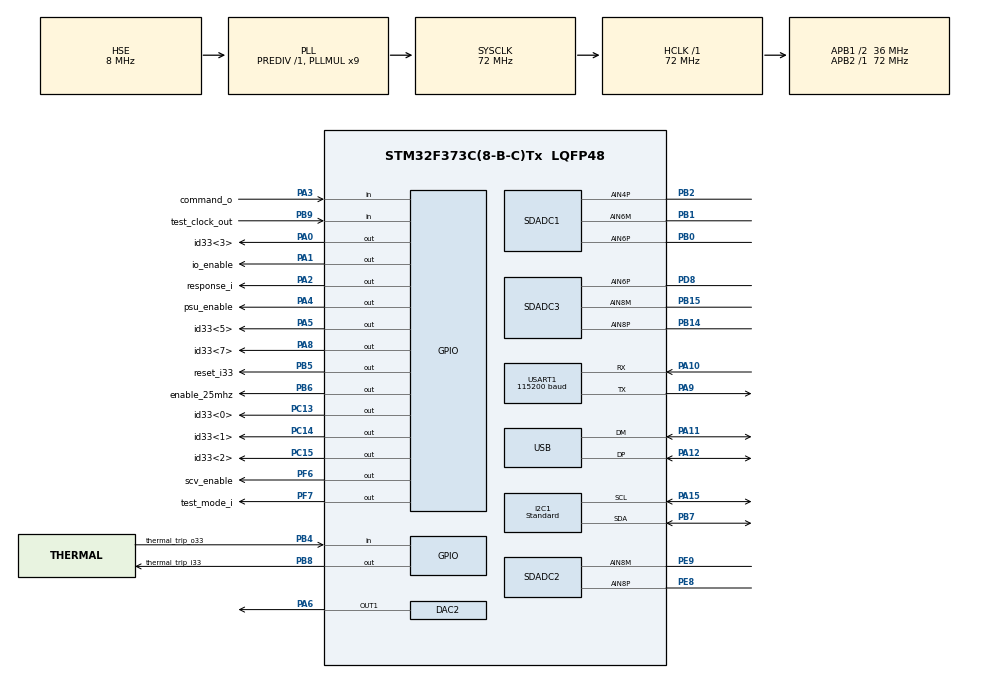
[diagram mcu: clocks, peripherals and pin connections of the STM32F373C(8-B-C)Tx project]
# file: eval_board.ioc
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ADC1.Channel-0\#ChannelRegularConversion=ADC_CHANNEL_TEMPSENSOR
ADC1.NbrOfConversionFlag=1
ADC1.Rank-0\#ChannelRegularConversion=1
ADC1.SamplingTime-0\#ChannelRegularConversion=ADC_SAMPLETIME_1CYCLE_5
ADC1.master=1
Dma.Request0=USART1_RX
Dma.Request1=USART1_TX
Dma.USART1_RX.0.Direction=DMA_PERIPH_TO_MEMORY
Dma.USART1_RX.0.Instance=DMA1_Channel5
Dma.USART1_RX.0.MemDataAlignment=DMA_MDATAALIGN_BYTE
Dma.USART1_RX.0.MemInc=DMA_MINC_ENABLE
Dma.USART1_RX.0.Mode=DMA_CIRCULAR
Dma.USART1_RX.0.PeriphDataAlignment=DMA_PDATAALIGN_BYTE
Dma.USART1_RX.0.PeriphInc=DMA_PINC_DISABLE
Dma.USART1_RX.0.Priority=DMA_PRIORITY_LOW
Dma.USART1_TX.1.Direction=DMA_MEMORY_TO_PERIPH
Dma.USART1_TX.1.Instance=DMA1_Channel4
Dma.USART1_TX.1.MemDataAlignment=DMA_MDATAALIGN_BYTE
Dma.USART1_TX.1.MemInc=DMA_MINC_ENABLE
Dma.USART1_TX.1.Mode=DMA_NORMAL
Dma.USART1_TX.1.PeriphDataAlignment=DMA_PDATAALIGN_BYTE
Dma.USART1_TX.1.PeriphInc=DMA_PINC_DISABLE
Dma.USART1_TX.1.Priority=DMA_PRIORITY_LOW
I2C1.I2C_Speed_Mode=I2C_Standard
Mcu.Family=STM32F3
Mcu.Name=STM32F373C(8-B-C)Tx
Mcu.Package=LQFP48
NVIC.DMA1_Channel4_IRQn=true\:0\:0\:false\:false\:true\:false\:true\:true
NVIC.DMA1_Channel5_IRQn=true\:0\:0\:false\:false\:true\:false\:true\:true
NVIC.PriorityGroup=NVIC_PRIORITYGROUP_4
NVIC.SDADC1_IRQn=true\:0\:0\:false\:false\:true\:true\:true\:true
NVIC.USART1_IRQn=true\:0\:0\:false\:false\:true\:true\:true\:true
NVIC.USB_LP_IRQn=true\:0\:0\:false\:false\:true\:false\:true\:true
PA0.GPIO_Label=id33<3>
PA0.Signal=GPIO_Output
PA1.GPIO_Label=io_enable
PA1.Signal=GPIO_Output
PA10.Mode=Asynchronous
PA10.Signal=USART1_RX
PA11.Mode=Device
PA11.Signal=USB_DM
PA12.Mode=Device
PA12.Signal=USB_DP
PA13.Mode=Trace_Asynchronous_SW
PA13.Signal=SYS_JTMS-SWDIO
PA14.Mode=Trace_Asynchronous_SW
PA14.Signal=SYS_JTCK-SWCLK
PA15.Mode=I2C
PA15.Signal=I2C1_SCL
PA2.GPIO_Label=response_i
PA2.Signal=GPIO_Output
PA3.GPIO_Label=command_o
PA3.Signal=GPIO_Input
PA4.GPIO_Label=psu_enable
PA4.Signal=GPIO_Output
PA5.GPIO_Label=id33<5>
PA5.Signal=GPIO_Output
PA6.Signal=COMP_DAC21_group
PA8.GPIO_Label=id33<7>
PA8.Signal=GPIO_Output
PA9.Mode=Asynchronous
PA9.Signal=USART1_TX
PB0.Mode=IN6-Differential
PB0.Signal=SDADC1_AIN6P
PB1.Mode=IN6-Differential
PB1.Signal=SDADC1_AIN6M
PB14.Mode=IN8-Differential
PB14.Signal=SDADC3_AIN8P
PB15.Mode=IN8-Differential
PB15.Signal=SDADC3_AIN8M
PB2.Mode=IN4-Single-Ended
PB2.Signal=SDADC1_AIN4P
PB3.Mode=Trace_Asynchronous_SW
PB3.Signal=SYS_JTDO-TRACESWO
PB4.GPIO_Label=thermal_trip_o33
PB4.GPIO_PuPd=GPIO_PULLUP
PB4.Signal=GPIO_Input
PB5.GPIO_Label=reset_i33
PB5.Signal=GPIO_Output
PB6.GPIO_Label=enable_25mhz
PB6.Signal=GPIO_Output
PB7.Mode=I2C
PB7.Signal=I2C1_SDA
PB8.GPIO_Label=thermal_trip_i33
PB8.Signal=GPIO_Output
PB9.GPIO_Label=test_clock_out
PB9.GPIO_PuPd=GPIO_PULLDOWN
PB9.Signal=GPIO_Input
PC13.GPIO_Label=id33<0>
PC13.Signal=GPIO_Output
PC14-OSC32_IN.GPIO_Label=id33<1>
PC14-OSC32_IN.Signal=GPIO_Output
PC15-OSC32_OUT.GPIO_Label=id33<2>
PC15-OSC32_OUT.Signal=GPIO_Output
PD8.Mode=IN6-Single-Ended
PD8.Signal=SDADC3_AIN6P
PE8.Mode=IN8-Differential
PE8.Signal=SDADC2_AIN8P
PE9.Mode=IN8-Differential
PE9.Signal=SDADC2_AIN8M
PF0-OSC_IN.Mode=HSE-External-Oscillator
PF0-OSC_IN.Signal=RCC_OSC_IN
PF1-OSC_OUT.Mode=HSE-External-Oscillator
PF1-OSC_OUT.Signal=RCC_OSC_OUT
PF6.GPIO_Label=scv_enable
PF6.Signal=GPIO_Output
PF7.GPIO_Label=test_mode_i
PF7.Signal=GPIO_Output
ProjectManager.HeapSize=0x800
ProjectManager.StackSize=0x800
ProjectManager.TargetToolchain=STM32CubeIDE
RCC.AHBFreq_Value=72000000
RCC.APB1CLKDivider=RCC_HCLK_DIV2
RCC.APB1Freq_Value=36000000
RCC.APB1TimFreq_Value=72000000
RCC.APB2Freq_Value=72000000
RCC.APB2TimFreq_Value=72000000
RCC.CortexFreq_Value=72000000
RCC.HCLKFreq_Value=72000000
RCC.HSE_VALUE=8000000
RCC.HSI_VALUE=8000000
RCC.LSE_VALUE=32768
RCC.PLLMUL=RCC_PLL_MUL9
RCC.PRESCALERUSB=RCC_USBCLKSOURCE_PLL_DIV1_5
RCC.SDADCPresc=RCC_SDADCSYSCLK_DIV12
RCC.SYSCLKFreq_VALUE=72000000
RCC.SYSCLKSource=RCC_SYSCLKSOURCE_PLLCLK
RCC.USBFreq_Value=48000000
SDADC1.Channel-0\#ChannelRegularConversion=SDADC_CHANNEL_6
SDADC1.ConfIndex-0\#ChannelRegularConversion=SDADC_CONF_INDEX_0
SDADC1.ContinuousMode=SDADC_CONTINUOUS_CONV_ON
SDADC1.EnableRegularconversion=ENABLE
SDADC1.FastConversionMode=SDADC_FAST_CONV_ENABLE
SDADC1.Gain0=SDADC_GAIN_8
SDADC1.Gain1=SDADC_GAIN_4
SDADC1.InputMode1=SDADC_INPUT_MODE_SE_OFFSET
SDADC1.NbrOfConversionFlag=1
SDADC1.ReferenceVoltage=SDADC_VREF_VDDA
SDADC2.ContinuousMode=SDADC_CONTINUOUS_CONV_ON
SDADC2.EnableRegularconversion=ENABLE
SDADC2.FastConversionMode=SDADC_FAST_CONV_ENABLE
SDADC2.Gain0=SDADC_GAIN_8
SDADC2.NbrOfConversionFlag=1
SDADC2.ReferenceVoltage=SDADC_VREF_VDDA
SDADC2.Trigger=SDADC_SOFTWARE_TRIGGER
SDADC3.Channel-0\#ChannelRegularConversion=SDADC_CHANNEL_8
SDADC3.ConfIndex-0\#ChannelRegularConversion=SDADC_CONF_INDEX_0
SDADC3.ContinuousMode=SDADC_CONTINUOUS_CONV_ON
SDADC3.EnableRegularconversion=ENABLE
SDADC3.FastConversionMode=SDADC_FAST_CONV_ENABLE
SDADC3.Gain0=SDADC_GAIN_8
SDADC3.Gain1=SDADC_GAIN_4
SDADC3.InputMode1=SDADC_INPUT_MODE_SE_OFFSET
SDADC3.NbrOfConversionFlag=1
SDADC3.ReferenceVoltage=SDADC_VREF_VDDA
SH.COMP_DAC21_group.0=DAC2_OUT1,DAC_OUT1
USART1.BaudRate=115200
USART1.OverSampling=UART_OVERSAMPLING_8
USART1.VirtualMode-Asynchronous=VM_ASYNC
USB_DEVICE.CLASS_NAME_FS=CDC
USB_DEVICE.VirtualMode=Cdc
USB_DEVICE.VirtualModeFS=Cdc_FS
VP_ADC1_TempSens_Input.Mode=IN-TempSens
VP_SDADC1_CONF0.Mode=ConfigZero
VP_SDADC1_CONF1.Mode=ConfigUn
VP_SDADC2_CONF0.Mode=ConfigZero
VP_SDADC3_CONF0.Mode=ConfigZero
VP_SDADC3_CONF1.Mode=ConfigUn
VP_USB_DEVICE_VS_USB_DEVICE_CDC_FS.Mode=CDC_FS
board=custom

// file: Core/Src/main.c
/* USER CODE BEGIN Header */
/**
  ******************************************************************************
  * @file           : main.c
  * @brief          : Main program body
  ******************************************************************************
  * @attention
  *
  * Copyright (c) 2022 STMicroelectronics.
  * All rights reserved.
  *
  * This software is licensed under terms that can be found in the LICENSE file
  * in the root directory of this software component.
  * If no LICENSE file comes with this software, it is provided AS-IS.
  *
  ******************************************************************************
  */
/* USER CODE END Header */
#include "main.h"
#include "usb_device.h"

/* USER CODE BEGIN Includes */
#include "../../../uctl_common/ssd1306.h"

/* USER CODE END Includes */

ADC_HandleTypeDef hadc1;

DAC_HandleTypeDef hdac2;

I2C_HandleTypeDef hi2c1;

SDADC_HandleTypeDef hsdadc1;
SDADC_HandleTypeDef hsdadc2;
SDADC_HandleTypeDef hsdadc3;

UART_HandleTypeDef huart1;
DMA_HandleTypeDef hdma_usart1_rx;
DMA_HandleTypeDef hdma_usart1_tx;

void SystemClock_Config(void);
static void MX_GPIO_Init(void);
static void MX_DMA_Init(void);
static void MX_SDADC1_Init(void);
static void MX_SDADC2_Init(void);
static void MX_USART1_UART_Init(void);
static void MX_DAC2_Init(void);
static void MX_I2C1_Init(void);
static void MX_SDADC3_Init(void);
static void MX_ADC1_Init(void);

/* USER CODE BEGIN 0 */
void Init();
void Loop();
/* USER CODE END 0 */

int main(void)
{

  /* MCU Configuration--------------------------------------------------------*/

  /* Reset of all peripherals, Initializes the Flash interface and the Systick. */
  HAL_Init();

  /* Configure the system clock */
  SystemClock_Config();

  /* Initialize all configured peripherals */
  MX_GPIO_Init();
  MX_DMA_Init();
  MX_SDADC1_Init();
  MX_SDADC2_Init();
  MX_USART1_UART_Init();
  MX_DAC2_Init();
  MX_USB_DEVICE_Init();
  MX_I2C1_Init();
  MX_SDADC3_Init();
  MX_ADC1_Init();
  /* USER CODE BEGIN 2 */

  Init();

  /* USER CODE END 2 */

  /* Infinite loop */
  while (1)
  {

    /* USER CODE BEGIN 3 */
      Loop();
  }
  /* USER CODE END 3 */
}

void SystemClock_Config(void)
{
  RCC_OscInitTypeDef RCC_OscInitStruct = {0};
  RCC_ClkInitTypeDef RCC_ClkInitStruct = {0};
  RCC_PeriphCLKInitTypeDef PeriphClkInit = {0};

  /** Initializes the RCC Oscillators according to the specified parameters
  * in the RCC_OscInitTypeDef structure.
  */
  RCC_OscInitStruct.OscillatorType = RCC_OSCILLATORTYPE_HSI|RCC_OSCILLATORTYPE_HSE;
  RCC_OscInitStruct.HSEState = RCC_HSE_ON;
  RCC_OscInitStruct.HSEPredivValue = RCC_HSE_PREDIV_DIV1;
  RCC_OscInitStruct.HSIState = RCC_HSI_ON;
  RCC_OscInitStruct.HSICalibrationValue = RCC_HSICALIBRATION_DEFAULT;
  RCC_OscInitStruct.PLL.PLLState = RCC_PLL_ON;
  RCC_OscInitStruct.PLL.PLLSource = RCC_PLLSOURCE_HSE;
  RCC_OscInitStruct.PLL.PLLMUL = RCC_PLL_MUL9;
  if (HAL_RCC_OscConfig(&RCC_OscInitStruct) != HAL_OK)
  {
    Error_Handler();
  }

  /** Initializes the CPU, AHB and APB buses clocks
  */
  RCC_ClkInitStruct.ClockType = RCC_CLOCKTYPE_HCLK|RCC_CLOCKTYPE_SYSCLK
                              |RCC_CLOCKTYPE_PCLK1|RCC_CLOCKTYPE_PCLK2;
  RCC_ClkInitStruct.SYSCLKSource = RCC_SYSCLKSOURCE_PLLCLK;
  RCC_ClkInitStruct.AHBCLKDivider = RCC_SYSCLK_DIV1;
  RCC_ClkInitStruct.APB1CLKDivider = RCC_HCLK_DIV2;
  RCC_ClkInitStruct.APB2CLKDivider = RCC_HCLK_DIV1;

  if (HAL_RCC_ClockConfig(&RCC_ClkInitStruct, FLASH_LATENCY_2) != HAL_OK)
  {
    Error_Handler();
  }
  PeriphClkInit.PeriphClockSelection = RCC_PERIPHCLK_USB|RCC_PERIPHCLK_USART1
                              |RCC_PERIPHCLK_I2C1|RCC_PERIPHCLK_ADC1
                              |RCC_PERIPHCLK_SDADC;
  PeriphClkInit.Usart1ClockSelection = RCC_USART1CLKSOURCE_PCLK2;
  PeriphClkInit.I2c1ClockSelection = RCC_I2C1CLKSOURCE_HSI;
  PeriphClkInit.USBClockSelection = RCC_USBCLKSOURCE_PLL_DIV1_5;
  PeriphClkInit.SdadcClockSelection = RCC_SDADCSYSCLK_DIV12;
  PeriphClkInit.Adc1ClockSelection = RCC_ADC1PCLK2_DIV2;

  if (HAL_RCCEx_PeriphCLKConfig(&PeriphClkInit) != HAL_OK)
  {
    Error_Handler();
  }
  HAL_PWREx_EnableSDADC(PWR_SDADC_ANALOG1);
  HAL_PWREx_EnableSDADC(PWR_SDADC_ANALOG2);
  HAL_PWREx_EnableSDADC(PWR_SDADC_ANALOG3);
}

static void MX_ADC1_Init(void)
{

  ADC_ChannelConfTypeDef sConfig = {0};

  /** Common config
  */
  hadc1.Instance = ADC1;
  hadc1.Init.ScanConvMode = ADC_SCAN_DISABLE;
  hadc1.Init.ContinuousConvMode = DISABLE;
  hadc1.Init.DiscontinuousConvMode = DISABLE;
  hadc1.Init.ExternalTrigConv = ADC_SOFTWARE_START;
  hadc1.Init.DataAlign = ADC_DATAALIGN_RIGHT;
  hadc1.Init.NbrOfConversion = 1;
  if (HAL_ADC_Init(&hadc1) != HAL_OK)
  {
    Error_Handler();
  }

  /** Configure Regular Channel
  */
  sConfig.Channel = ADC_CHANNEL_TEMPSENSOR;
  sConfig.Rank = ADC_REGULAR_RANK_1;
  sConfig.SamplingTime = ADC_SAMPLETIME_1CYCLE_5;
  if (HAL_ADC_ConfigChannel(&hadc1, &sConfig) != HAL_OK)
  {
    Error_Handler();
  }

}

static void MX_DAC2_Init(void)
{

  DAC_ChannelConfTypeDef sConfig = {0};

  /** DAC Initialization
  */
  hdac2.Instance = DAC2;
  if (HAL_DAC_Init(&hdac2) != HAL_OK)
  {
    Error_Handler();
  }

  /** DAC channel OUT1 config
  */
  sConfig.DAC_Trigger = DAC_TRIGGER_NONE;
  sConfig.DAC_OutputBuffer = DAC_OUTPUTBUFFER_ENABLE;
  if (HAL_DAC_ConfigChannel(&hdac2, &sConfig, DAC_CHANNEL_1) != HAL_OK)
  {
    Error_Handler();
  }

}

static void MX_I2C1_Init(void)
{

  hi2c1.Instance = I2C1;
  hi2c1.Init.Timing = 0x2000090E;
  hi2c1.Init.OwnAddress1 = 0;
  hi2c1.Init.AddressingMode = I2C_ADDRESSINGMODE_7BIT;
  hi2c1.Init.DualAddressMode = I2C_DUALADDRESS_DISABLE;
  hi2c1.Init.OwnAddress2 = 0;
  hi2c1.Init.OwnAddress2Masks = I2C_OA2_NOMASK;
  hi2c1.Init.GeneralCallMode = I2C_GENERALCALL_DISABLE;
  hi2c1.Init.NoStretchMode = I2C_NOSTRETCH_DISABLE;
  if (HAL_I2C_Init(&hi2c1) != HAL_OK)
  {
    Error_Handler();
  }

  /** Configure Analogue filter
  */
  if (HAL_I2CEx_ConfigAnalogFilter(&hi2c1, I2C_ANALOGFILTER_ENABLE) != HAL_OK)
  {
    Error_Handler();
  }

  /** Configure Digital filter
  */
  if (HAL_I2CEx_ConfigDigitalFilter(&hi2c1, 0) != HAL_OK)
  {
    Error_Handler();
  }

}

static void MX_SDADC1_Init(void)
{

  SDADC_ConfParamTypeDef ConfParamStruct = {0};

  /** Configure the SDADC low power mode, fast conversion mode,
  slow clock mode and SDADC1 reference voltage
  */
  hsdadc1.Instance = SDADC1;
  hsdadc1.Init.IdleLowPowerMode = SDADC_LOWPOWER_NONE;
  hsdadc1.Init.FastConversionMode = SDADC_FAST_CONV_ENABLE;
  hsdadc1.Init.SlowClockMode = SDADC_SLOW_CLOCK_DISABLE;
  hsdadc1.Init.ReferenceVoltage = SDADC_VREF_VDDA;
  if (HAL_SDADC_Init(&hsdadc1) != HAL_OK)
  {
    Error_Handler();
  }

  /** Configure The Regular Mode
  */
  if (HAL_SDADC_SelectRegularTrigger(&hsdadc1, SDADC_SOFTWARE_TRIGGER) != HAL_OK)
  {
    Error_Handler();
  }

  /** Set parameters for SDADC configuration 0 Register
  */
  ConfParamStruct.InputMode = SDADC_INPUT_MODE_DIFF;
  ConfParamStruct.Gain = SDADC_GAIN_8;
  ConfParamStruct.CommonMode = SDADC_COMMON_MODE_VSSA;
  ConfParamStruct.Offset = 0;
  if (HAL_SDADC_PrepareChannelConfig(&hsdadc1, SDADC_CONF_INDEX_0, &ConfParamStruct) != HAL_OK)
  {
    Error_Handler();
  }

  /** Set parameters for SDADC configuration 1 Register
  */
  ConfParamStruct.InputMode = SDADC_INPUT_MODE_SE_OFFSET;
  ConfParamStruct.Gain = SDADC_GAIN_4;
  if (HAL_SDADC_PrepareChannelConfig(&hsdadc1, SDADC_CONF_INDEX_1, &ConfParamStruct) != HAL_OK)
  {
    Error_Handler();
  }

  /** Configure the Regular Channel
  */
  if (HAL_SDADC_AssociateChannelConfig(&hsdadc1, SDADC_CHANNEL_6, SDADC_CONF_INDEX_0) != HAL_OK)
  {
    Error_Handler();
  }
  if (HAL_SDADC_ConfigChannel(&hsdadc1, SDADC_CHANNEL_6, SDADC_CONTINUOUS_CONV_ON) != HAL_OK)
  {
    Error_Handler();
  }

}

static void MX_SDADC2_Init(void)
{

  SDADC_ConfParamTypeDef ConfParamStruct = {0};

  /** Configure the SDADC low power mode, fast conversion mode,
  slow clock mode and SDADC1 reference voltage
  */
  hsdadc2.Instance = SDADC2;
  hsdadc2.Init.IdleLowPowerMode = SDADC_LOWPOWER_NONE;
  hsdadc2.Init.FastConversionMode = SDADC_FAST_CONV_ENABLE;
  hsdadc2.Init.SlowClockMode = SDADC_SLOW_CLOCK_DISABLE;
  hsdadc2.Init.ReferenceVoltage = SDADC_VREF_VDDA;
  if (HAL_SDADC_Init(&hsdadc2) != HAL_OK)
  {
    Error_Handler();
  }

  /** Configure The Regular Mode
  */
  if (HAL_SDADC_SelectRegularTrigger(&hsdadc2, SDADC_SOFTWARE_TRIGGER) != HAL_OK)
  {
    Error_Handler();
  }

  /** Set parameters for SDADC configuration 0 Register
  */
  ConfParamStruct.InputMode = SDADC_INPUT_MODE_DIFF;
  ConfParamStruct.Gain = SDADC_GAIN_8;
  ConfParamStruct.CommonMode = SDADC_COMMON_MODE_VSSA;
  ConfParamStruct.Offset = 0;
  if (HAL_SDADC_PrepareChannelConfig(&hsdadc2, SDADC_CONF_INDEX_0, &ConfParamStruct) != HAL_OK)
  {
    Error_Handler();
  }

}

static void MX_SDADC3_Init(void)
{

  SDADC_ConfParamTypeDef ConfParamStruct = {0};

  /** Configure the SDADC low power mode, fast conversion mode,
  slow clock mode and SDADC1 reference voltage
  */
  hsdadc3.Instance = SDADC3;
  hsdadc3.Init.IdleLowPowerMode = SDADC_LOWPOWER_NONE;
  hsdadc3.Init.FastConversionMode = SDADC_FAST_CONV_ENABLE;
  hsdadc3.Init.SlowClockMode = SDADC_SLOW_CLOCK_DISABLE;
  hsdadc3.Init.ReferenceVoltage = SDADC_VREF_VDDA;
  if (HAL_SDADC_Init(&hsdadc3) != HAL_OK)
  {
    Error_Handler();
  }

  /** Configure The Regular Mode
  */
  if (HAL_SDADC_SelectRegularTrigger(&hsdadc3, SDADC_SOFTWARE_TRIGGER) != HAL_OK)
  {
    Error_Handler();
  }

  /** Set parameters for SDADC configuration 0 Register
  */
  ConfParamStruct.InputMode = SDADC_INPUT_MODE_DIFF;
  ConfParamStruct.Gain = SDADC_GAIN_8;
  ConfParamStruct.CommonMode = SDADC_COMMON_MODE_VSSA;
  ConfParamStruct.Offset = 0;
  if (HAL_SDADC_PrepareChannelConfig(&hsdadc3, SDADC_CONF_INDEX_0, &ConfParamStruct) != HAL_OK)
  {
    Error_Handler();
  }

  /** Set parameters for SDADC configuration 1 Register
  */
  ConfParamStruct.InputMode = SDADC_INPUT_MODE_SE_OFFSET;
  ConfParamStruct.Gain = SDADC_GAIN_4;
  if (HAL_SDADC_PrepareChannelConfig(&hsdadc3, SDADC_CONF_INDEX_1, &ConfParamStruct) != HAL_OK)
  {
    Error_Handler();
  }

  /** Configure the Regular Channel
  */
  if (HAL_SDADC_AssociateChannelConfig(&hsdadc3, SDADC_CHANNEL_8, SDADC_CONF_INDEX_0) != HAL_OK)
  {
    Error_Handler();
  }
  if (HAL_SDADC_ConfigChannel(&hsdadc3, SDADC_CHANNEL_8, SDADC_CONTINUOUS_CONV_ON) != HAL_OK)
  {
    Error_Handler();
  }

}

static void MX_USART1_UART_Init(void)
{

  huart1.Instance = USART1;
  huart1.Init.BaudRate = 115200;
  huart1.Init.WordLength = UART_WORDLENGTH_8B;
  huart1.Init.StopBits = UART_STOPBITS_1;
  huart1.Init.Parity = UART_PARITY_NONE;
  huart1.Init.Mode = UART_MODE_TX_RX;
  huart1.Init.HwFlowCtl = UART_HWCONTROL_NONE;
  huart1.Init.OverSampling = UART_OVERSAMPLING_8;
  huart1.Init.OneBitSampling = UART_ONE_BIT_SAMPLE_DISABLE;
  huart1.AdvancedInit.AdvFeatureInit = UART_ADVFEATURE_NO_INIT;
  if (HAL_UART_Init(&huart1) != HAL_OK)
  {
    Error_Handler();
  }

}

static void MX_DMA_Init(void)
{

  /* DMA controller clock enable */
  __HAL_RCC_DMA1_CLK_ENABLE();

  /* DMA interrupt init */
  /* DMA1_Channel4_IRQn interrupt configuration */
  HAL_NVIC_SetPriority(DMA1_Channel4_IRQn, 0, 0);
  HAL_NVIC_EnableIRQ(DMA1_Channel4_IRQn);
  /* DMA1_Channel5_IRQn interrupt configuration */
  HAL_NVIC_SetPriority(DMA1_Channel5_IRQn, 0, 0);
  HAL_NVIC_EnableIRQ(DMA1_Channel5_IRQn);

}

static void MX_GPIO_Init(void)
{
  GPIO_InitTypeDef GPIO_InitStruct = {0};

  /* GPIO Ports Clock Enable */
  __HAL_RCC_GPIOC_CLK_ENABLE();
  __HAL_RCC_GPIOF_CLK_ENABLE();
  __HAL_RCC_GPIOA_CLK_ENABLE();
  __HAL_RCC_GPIOB_CLK_ENABLE();
  __HAL_RCC_GPIOE_CLK_ENABLE();
  __HAL_RCC_GPIOD_CLK_ENABLE();

  /*Configure GPIO pin Output Level */
  HAL_GPIO_WritePin(GPIOC, id33_0__Pin|id33_1__Pin|id33_2__Pin, GPIO_PIN_RESET);

  /*Configure GPIO pin Output Level */
  HAL_GPIO_WritePin(GPIOA, id33_3__Pin|io_enable_Pin|response_i_Pin|psu_enable_Pin
                          |id33_5__Pin|id33_7__Pin, GPIO_PIN_RESET);

  /*Configure GPIO pin Output Level */
  HAL_GPIO_WritePin(GPIOF, scv_enable_Pin|test_mode_i_Pin, GPIO_PIN_RESET);

  /*Configure GPIO pin Output Level */
  HAL_GPIO_WritePin(GPIOB, reset_i33_Pin|enable_25mhz_Pin|thermal_trip_i33_Pin, GPIO_PIN_RESET);

  /*Configure GPIO pins : id33_0__Pin id33_1__Pin id33_2__Pin */
  GPIO_InitStruct.Pin = id33_0__Pin|id33_1__Pin|id33_2__Pin;
  GPIO_InitStruct.Mode = GPIO_MODE_OUTPUT_PP;
  GPIO_InitStruct.Pull = GPIO_NOPULL;
  GPIO_InitStruct.Speed = GPIO_SPEED_FREQ_LOW;
  HAL_GPIO_Init(GPIOC, &GPIO_InitStruct);

  /*Configure GPIO pins : id33_3__Pin io_enable_Pin response_i_Pin psu_enable_Pin
                           id33_5__Pin id33_7__Pin */
  GPIO_InitStruct.Pin = id33_3__Pin|io_enable_Pin|response_i_Pin|psu_enable_Pin
                          |id33_5__Pin|id33_7__Pin;
  GPIO_InitStruct.Mode = GPIO_MODE_OUTPUT_PP;
  GPIO_InitStruct.Pull = GPIO_NOPULL;
  GPIO_InitStruct.Speed = GPIO_SPEED_FREQ_LOW;
  HAL_GPIO_Init(GPIOA, &GPIO_InitStruct);

  /*Configure GPIO pin : command_o_Pin */
  GPIO_InitStruct.Pin = command_o_Pin;
  GPIO_InitStruct.Mode = GPIO_MODE_INPUT;
  GPIO_InitStruct.Pull = GPIO_NOPULL;
  HAL_GPIO_Init(command_o_GPIO_Port, &GPIO_InitStruct);

  /*Configure GPIO pins : scv_enable_Pin test_mode_i_Pin */
  GPIO_InitStruct.Pin = scv_enable_Pin|test_mode_i_Pin;
  GPIO_InitStruct.Mode = GPIO_MODE_OUTPUT_PP;
  GPIO_InitStruct.Pull = GPIO_NOPULL;
  GPIO_InitStruct.Speed = GPIO_SPEED_FREQ_LOW;
  HAL_GPIO_Init(GPIOF, &GPIO_InitStruct);

  /*Configure GPIO pin : thermal_trip_o33_Pin */
  GPIO_InitStruct.Pin = thermal_trip_o33_Pin;
  GPIO_InitStruct.Mode = GPIO_MODE_INPUT;
  GPIO_InitStruct.Pull = GPIO_PULLUP;
  HAL_GPIO_Init(thermal_trip_o33_GPIO_Port, &GPIO_InitStruct);

  /*Configure GPIO pins : reset_i33_Pin enable_25mhz_Pin thermal_trip_i33_Pin */
  GPIO_InitStruct.Pin = reset_i33_Pin|enable_25mhz_Pin|thermal_trip_i33_Pin;
  GPIO_InitStruct.Mode = GPIO_MODE_OUTPUT_PP;
  GPIO_InitStruct.Pull = GPIO_NOPULL;
  GPIO_InitStruct.Speed = GPIO_SPEED_FREQ_LOW;
  HAL_GPIO_Init(GPIOB, &GPIO_InitStruct);

  /*Configure GPIO pin : test_clock_out_Pin */
  GPIO_InitStruct.Pin = test_clock_out_Pin;
  GPIO_InitStruct.Mode = GPIO_MODE_INPUT;
  GPIO_InitStruct.Pull = GPIO_PULLDOWN;
  HAL_GPIO_Init(test_clock_out_GPIO_Port, &GPIO_InitStruct);

}

void Error_Handler(void)
{
  __disable_irq();
  while (1)
  {
  }
}
